# CCG2 register map
File version: 1.0
CPU: CM0 r1p0, little endian, no MPU, no FPU, 2 interrupt priority bits
Registers are 32-bit, read-write, reset 0x0 unless marked. A register's access mark holds for its fields unless they carry their own. Offsets are from the block's base; [hi:lo] are bit positions; {n}, {i} and the like mark numbered series; <NAME> marks a mode.

## CPUSS
Base 0x40100000
0x00 CONFIG — Configuration register
  [0] VECT_IN_RAM — 0': Vector Table is located at 0x0000:0000 in flash '1': Vector Table is located at 0x2000:0000 in SRAM Note that vectors for RESET and FAULT are always fetched from ROM. Value in flash/RAM is ignored for these vectors.
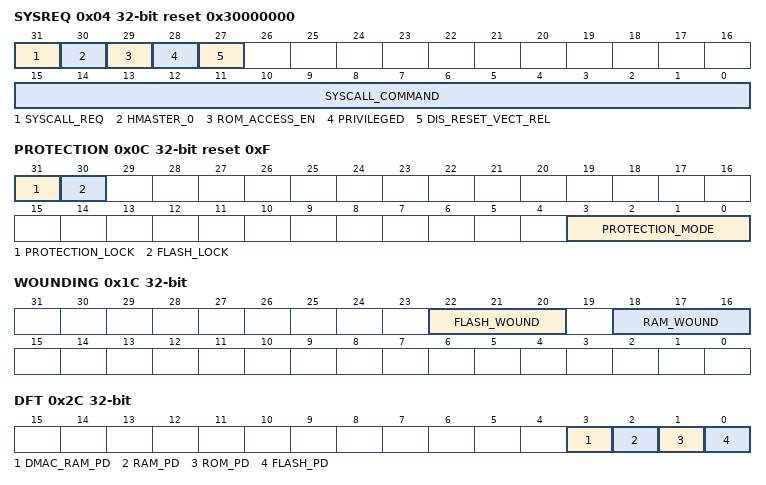
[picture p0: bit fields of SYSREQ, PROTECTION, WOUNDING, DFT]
0x04 SYSREQ reset 0x30000000 — SYSCALL control register Used to make system requests to SROM code. System Requests transition from User Mode to Privileged Mode. See SAS for more details. Firmware/ATE should write CPUSS_SYSARG first and CPUSS_SYSREQ register next.
  [31] SYSCALL_REQ — CPU/DAP writes a '1' to this field to request a SystemCall. The HMASTER_0 field indicates the source of the write access. Setting this field to '1' immediate results in a NMI. The SystemCall NMI interrupt handler sets this field to '0' after servicing the request.
  [30] HMASTER_0 ro — Indicates the source of the write access to the SYSREQ register. '0': CPU write access. '1': DAP write access. HW sets this field when the SYSREQ register is written to and SYSCALL_REQ is '0' (the last time it is set is when SW sets SYSCALL_REQ from '0' to '1').
  [29] ROM_ACCESS_EN ro — Indicates that executing from Boot ROM is enabled. HW sets this field to '1', on reset or when the SystemCall NMI vector is fetched from Boot ROM. HW sets this field to '0', when the CPU is NOT executing from either Boot or System ROM. This bit is used for debug purposes only.
  [28] PRIVILEGED — Indicates whether the system is in privileged ('1') or user mode ('0'). Only CPU SW executing from ROM can set this field to '1' when ROM_ACCESS_EN is '1' (the CPU is executing a SystemCall NMI interrupt handler). Any other write to this field sets is to '0'. This field is used as the AHB-Lite hprot[1] signal to implement Cypress proprietary user/privileged modes. These modes are used to enable/disable access to specific MMIO registers and memory regions.
  [27] DIS_RESET_VECT_REL — Disable Reset Vector fetch relocation: '0': CPU accesses to locations 0x0000:0000 - 0x0000:0007 are redirected to ROM. '1': CPU accesses to locations 0x0000:0000 - 0x0000:0007 are made to flash. Note that this field defaults to '0' on reset, ensuring actual reset vector fetches are always made to ROM. Note that this field does not affect DAP accesses. Flash DfT routines may set this bit to '1' to enable uninhibited read-back of programmed data in the first flash page.
  [15:0] SYSCALL_COMMAND — Opcode of the system call being requested.
0x08 SYSARG — SYSARG control register Used to make system requests to SROM code. System Requests transition from User Mode to Privileged Mode. See SAS for more details. Firmware/ATE should write CPUSS_SYSARG first and CPUSS_SYSREQ register next.
  [31:0] SYSCALL_ARG — Argument to System Call specified in SYSREQ. Semantics of argument depends on system call made. Typically a pointer to a parameter block.
0x0C PROTECTION reset 0xF — Protection control register
  [31] PROTECTION_LOCK write-1-sets — Setting this field will block (ignore) any further writes to the PROTECTION_MODE field in this register. Once '1', this field cannot be cleared.
  [30] FLASH_LOCK — Setting this bit will force SPCIF.ADDRESS.AXA to be ignored, which prevents SM Flash from being erased or overwritten. It is used to indicate the DEAD protection mode. Writes to this field are ignored when PROTECTION_LOCK is '1'
  [3:0] PROTECTION_MODE — Current protection mode; this field is available as a global signal everywhere in the system. Writes to this field are ignored when PROTECTION_LOCK is '1': 0b1xxx: BOOT 0b01xx: KILL 0b001x: PROTECTED 0b0001: OPEN 0b0000: VIRGIN (also used for DEAD mode, but then FLASH_LOCK is also set)
0x10 PRIV_ROM — ROM privilege register ROM memory has a maximum capacity of 128 KByte. ROM is partitioned into Boot ROM and System ROM. These two partitions are located back-to-back in the system address space. The Boot ROM capacity is 4, 8, 16, or 32 KByte. The System ROM partition capacity equals the ROM capacity minus the Boot ROM partition capacity. User mode accesses to a privileged address result in an AHB-Lite bus error. If the ROM memory capacity is not a power of two, the ROM memory region has an unpopulated/unaccounted memory are (at the end of the ROM memory region). A user mode access to an unpopulated, privileged area (as indicated by the LIMIT field(s)) address results in an AHB-Lite bus error. A user mode access to a unpopulated area, without any access violations, behaves as follows: Reads return "0" and writes are ignore (RZWI).
  [7:0] BROM_PROT_LIMIT — Indicates the limit where the privileged area of the Boot ROM partition starts in increments of 256 Bytes. "0": Entire Boot ROM is Privileged. "1": First 256 Bytes are User accessable. ... BROM_PROT_LIMIT >= "Boot ROM partition capacity": Entire Boot ROM partition is user mode accessible.
0x14 PRIV_RAM — RAM privilege register User mode accesses to a privileged address result in an AHB-Lite bus error. If the RAM memory capacity is not a power of two, the RAM memory region has an unpopulated/unaccounted memory are (at the end of the RAM memory region). A user mode access to an unpopulated, privileged area (as indicated by the LIMIT field(s)) address results in an AHB-Lite bus error. A user mode access to a unpopulated area, without any access violations, behaves as follows: Reads return "0" and writes are ignore (RZWI).
  [8:0] RAM_PROT_LIMIT — Indicates the limit where the privileged area of SRAM starts in increments of 256 Bytes. "0": Entire SRAM is Privileged. "1": First 256 Bytes are User accessable. Any number larger than the size of the SRAM indicates that the entire SRAM is user mode accessible.
0x18 PRIV_FLASH — ROM privilege register User mode accesses to a privileged address result in an+C48 AHB-Lite bus error. If the regular flash memory capacity is not a power of two, the regular flash memory region has an unpopulated/unaccounted memory are (at the end of the regular flash memory region). A user mode access to an unpopulated, privileged area (as indicated by the LIMIT field(s)) address results in an AHB-Lite bus error. A user mode access to a unpopulated area, without any access violations, behaves as follows: Reads return "0" and writes are ignore (RZWI).
  [10:0] FLASH_PROT_LIMIT — Indicates the limit where the privileged area of flash starts in increments of 256 Bytes. "0": Entire flash is Privileged. "1": First 256 Bytes are User accessable. Any number larger than the size of the flash indicates that the entire flash is user mode accessible. Note that SuperVisory rows are always User accessable. If FLASH_PROT_LIMIT defines a non-empty privileged area, the boot ROM will assume that a system call table exists at the beginning of the Flash privileged area and use it for all SystemCalls made using SYSREQ.
0x1C WOUNDING — Wounding register Wounding is based on the FLASH/SRAM memory address range. This range is always the next power of 2 multiple of the FLASH/SRAM memory capacity. E.g., a 48 KByte SRAM capacity has a 64 KByte memory address range. With RAM_WOUND is "0", all 48 KByte SRAM capacity is accessible. With RAM_WOUND is "1", the first 32 KByte SRAM capacity is accessible. With RAM_WOUND is "2", the first 16 KByte SRAM capacity is accessible.
  [22:20] FLASH_WOUND write-1-sets — Indicates the amount of accessible flash in this part. The value in this field is effectively write-once (it is only possible to set bits, not clear them). The remainder portion of flash is not accessible and will return an AHB-Lite bus error. "0": entire memory accessible "1": first 1/2 of the memory accessible "2": first 1/4 of the memory accessible "3": first 1/8 of the memory accessible "4": first 1/16 of the memory accessible "5": first 1/32 of the memory accessible "6": first 1/64 of the memory accessible "7": first 1/128 of the memory accessible (used for the DEAD protection mode)
  [18:16] RAM_WOUND write-1-sets — Indicates the amount of accessible RAM 0 memory capacitty in this part. The value in this field is effectively write-once (it is only possible to set bits, not clear them). The remainder portion of SRAM is not accessible and will return an AHB-Lite bus error. "0": entire memory accessible "1": first 1/2 of the memory accessible "2": first 1/4 of the memory accessible "3": first 1/8 of the memory accessible "4": first 1/16 of the memory accessible "5": first 1/32 of the memory accessible "6": first 1/64 of the memory accessible "7": first 1/128 of the memory accessible
0x2C DFT — DFT Select Register Controls power switches of FLASH, ROM, SRAM macro(s) in CPUMEMSS. Note that for StreetFighther this functionality is NOT available due to an omission during IP development.
  [3] DMAC_RAM_PD — Forcibly powers down DW/DMA controller SRAM macro(s) (memory array and pheriphery) when set and TEST_MODE is active.
  [2] RAM_PD — Forcibly powers down system SRAM macro(s) periphery logic when set and TEST_MODE is active. Memory array is connected to Vcchib and cannot be powered down.
  [1] ROM_PD — Forcibly powers down system ROM macro(s) when set and TEST_MODE is active.
  [0] FLASH_PD — Forcibly powers down Flash macro(s) when set and TEST_MODE is active.
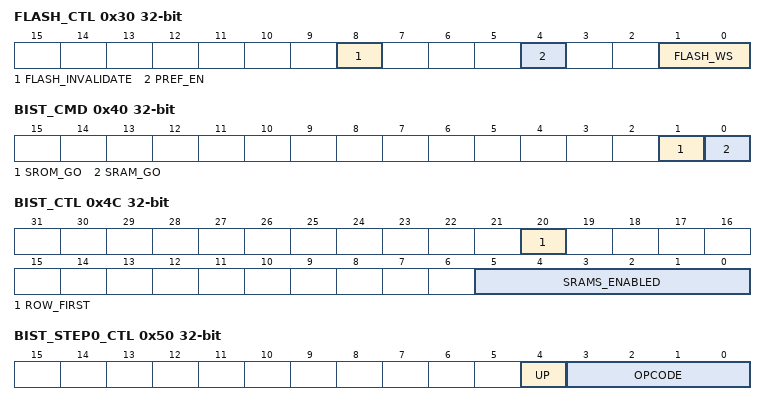
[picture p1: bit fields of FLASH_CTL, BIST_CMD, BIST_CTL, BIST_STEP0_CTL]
0x30 FLASH_CTL — FLASH control register
  [8] FLASH_INVALIDATE — 1': Invalidates the content of the flash controller's buffers.
  [4] PREF_EN — Prefetch enable: '0': disabled. This is a desirable seeting when FLASH_WS is "0" or when predictable execution behavior is required. '1': enabled.
  [1:0] FLASH_WS — Amount of ROM wait states: "0": 0 wait states (fast flash: [0, 24] MHz system frequency, slow flash: [0, 16] MHz system frequency) "1": 1 wait state (fast flash: [24, 48] MHz system frequency, slow flash: [16, 32] MHz system frequency) "2": 2 wait states (slow flash: [32, 48] MHz system frequency) "3": undefined
0x34 ROM_CTL — ROM control register
  [0] ROM_WS — Amount of ROM wait states: '0': 0 wait states. Use this setting for newer, faster ROM design. Use this setting for older, slower ROM design and frequencies in the range [0, 24] MHz. '1': 1 wait state. Use this setting for older, slower ROM design and frequencies in the range <24, 48] MHz. CPUSSv2 supports two types of ROM memory: an older, slower design (operating at up to 24 MHz) and a newer, faster design (operating at up to 48 MHz). The older design requires 1 wait state for frequencies above 24 MHz. The newer design never requires wait states. All chips after Street Fighter will use the newer design. As a result, all chips after Street Fighter can always use 0 wait states.
0x40 BIST_CMD — Bist command register
  [1] SROM_GO — 1': Start ROM BIST. Hardware set this field to '0' when BIST is completed. SROM BIST is functional up to 24 MHz.
  [0] SRAM_GO — 1': Start SRAM BIST. Hardware set this field to '0' when BIST is completed. SRAM BIST is functional up to 48 MHz. Note that this field is mutually exclusive with the "SROM_GO" field.
0x44 BIST_DATA
  [31:0] DATA — Data that is written into a SRAM during a W0 substep (~BIST_DATA.DATA is written into a SRAM during a W1 substep).
0x4C BIST_CTL — BIST control register
  [20] ROW_FIRST — Specifies how the SRAM BIST addresses are generated (should be set to '0' for SROM BIST): '0': Column address is incremented/decremented till it reaches its maximum/minimum value. Once it reach its maximum/minimum value, it is set to its mimimum/maximum value and only then is the row address incremented/decremented. '1': Row address is incremented/decremented till it reaches its maximum/minimum value. Once it reach its maximum/minimum value, it is set to its mimimum/maximum value and only then is the column address incremented/decremented.
  [5:0] SRAMS_ENABLED — Hot-one mask for the SRAMs for which the BIST is performed.
    1=SRAM_CPUSS_MASK; 2=SRAM_DMAC_MASK; 4=EXT_SRAM_0_MASK; 8=EXT_SRAM_1_MASK; 16=EXT_SRAM_2_MASK; 32=EXT_SRAM_3_MASK
0x50 BIST_STEP0_CTL — BIST step 0 control register
  [4] UP — Specifies direction in which SRAM BIST steps through addresses (not used for SROM BIST): ''0': BIST steps through the SRAM from the maximum row and column addresses (as specified by a design time configurtion parameter when ADDR_START_ENABLED is '0' and as specified by BIST_ADDR_START when ADDR_START_ENABLED is '1') to the minimum row and column addresses. '1': BIST steps through the SRAM from the minimum row and column addresses ("0" when ADDR_START_ENABLED is '0' and as specified by BIST_ADDR_START when ADDR_START_ENABLED is '1') to the maximum row and column addresses.
  [3:0] OPCODE — Specifies what sequence of SRAM BIST steps (R0, R1, W0, W1) is performed (not used for SROM BIST): "0": W0. Write SRAM with BIST_DATA.DATA. "1": W1. Write SRAM with ~BIST_DATA.DATA. "2": R0. Read SRAM and compare output to BIST_DATA.DATA. "3": R1. Read SRAM and compare output to ~BIST_DATA.DATA. "4": W0, R0. Write SRAM with BIST_DATA.DATA, followed by read SRAM and compare output to BIST_DATA.DATA (all to the same address). "5": R0, W1. "6": R1, W0. "7": R0, W1, R1. "8": R1, W0, R0. "9": R0, W1, W0. "10": R1, W0, W1. "11": R0, W1, W0, W1. "12": R1, W0, W1, W0. "13": R0, W1, R1, W0. "14": R1, W0, R0, W1. "15": R0, W1, R1, W0, R0, W1.
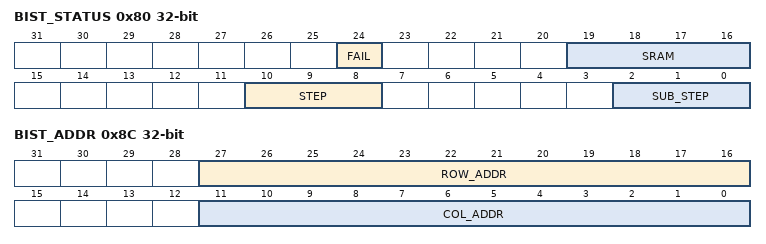
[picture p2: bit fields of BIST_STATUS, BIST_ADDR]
0x80 BIST_STATUS (reset mask 0x1000000)
  [24] FAIL — 0': BIST passed. '1': BIST failed (SRAM match error or ROM MISR check error). BIST error information is found in SRAM, STEP, SUB_STEP fields and BIST_DATA_ACT, BIST_DATA_EXP and BIST_ADDR registers.
  [19:16] SRAM ro — SRAM identifier.
    0=SRAM_CPUSS; 1=SRAM_DMAC; {v}=EXT_SRAM_{v-2} (v=2..15)
  [10:8] STEP ro — BIST step (step i uses BIST_STEPi_CTL).
  [2:0] SUB_STEP ro — BIST substep (either R0, R1, W0, or W1).
0x84 BIST_DATA_ACT reset not defined — BIST data expected register
  [31:0] DATA ro — For SRAM BIST, this field is the SRAM output data that caused a BIST failure. For ROM BIST, this field is the calculated Mulitple Input Shift Register (MISR).
0x88 BIST_DATA_EXP reset not defined — BIST data actual register
  [31:0] DATA ro — For SRAM BIST. This field is the expected data from SRAM. This value is BIST_DATA.DATA for a R0 substep and ~BIST_DATA.DATA for a R1 substep.
0x8C BIST_ADDR reset not defined — BIST address register
  [27:16] ROW_ADDR ro — Current row address.
  [11:0] COL_ADDR ro — Current column address.
0x90 BIST_MISR reset not defined — BIST SROM Multiple Input Shift Register (MISR)
  [31:0] DATA ro — Current value of ROM Multiple Input Shift Register (MISR).
0xC0 PTM_CTL — Parallel Test Mode Control Register This register determines the test interface (SWD or PTM) that connects the ATE to the device.
  [0] PTM_EN — 0': SWD mode. '1': PTM mode. This bit is typically set to '1' through the SWD interface to switch to the PTM interface and it is typically set to '0' through the PTM interface to switch to the SWD interface. This bit replaces the m0s8tst IP's CTRL.PTM_MODE_EN MMIO register field, which is rendered ineffective when using CPUSSv2.
